# APM32F411 register map
Vendor: Geehy; File version: 2024.11.05
CPU: CM4 r1p0, little endian, 3 interrupt priority bits
Registers are 32-bit, read-write, reset 0x0 unless marked. A register's access mark holds for its fields unless they carry their own. Offsets are from the block's base; [hi:lo] are bit positions; {n}, {i} and the like mark numbered series.

## MPU — Memory Protection Unit
Base 0xE000ED90
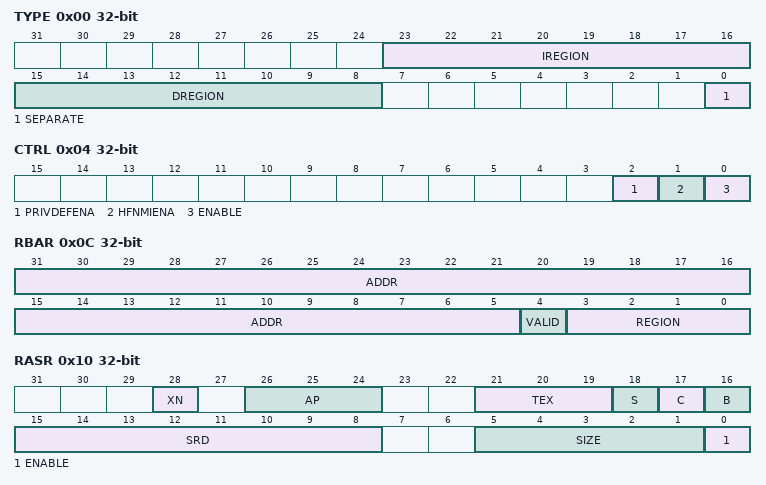
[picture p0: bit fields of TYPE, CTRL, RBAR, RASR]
0x00 TYPE ro — MPU Type Register
  [23:16] IREGION — Number of instruction regions supported
  [15:8] DREGION — Number of data regions supported
  [0] SEPARATE — Indicates support for separate instruction and data regions
0x04 CTRL — MPU Control Register
  [2] PRIVDEFENA — Enables the default memory map for privileged code
  [1] HFNMIENA — Enables MPU during Hard Fault and NMI
  [0] ENABLE — Enables the MPU
0x08 RNR — MPU Region Number Register
  [7:0] REGION — Indicates the region number to configure
0x0C RBAR (reset mask 0x8FFFFFFF) — MPU Region Base Address Register
  [31:5] ADDR — Base address of the region
  [4] VALID — Validates the region number field
  [3:0] REGION — Region number to configure
0x10 RASR — MPU Region Attribute and Size Register
  [28] XN — Instruction access disable
  [26:24] AP — Access permissions
  [21:19] TEX — Type extension field
  [18] S — Sharable attribute
  [17] C — Cacheable attribute
  [16] B — Bufferable attribute
  [15:8] SRD — Subregion disable bits
  [5:1] SIZE — Size of the region
  [0] ENABLE — Enables the region
{0xC+8i} RBAR_A{i} (i=1..3) — MPU Alias {i} Region Base Address Register
{0x10+8i} RASR_A{i} (i=1..3) — MPU Alias {i} Region Attribute and Size Register

## FPU — Floating Point Unit
Base 0xE000EF34
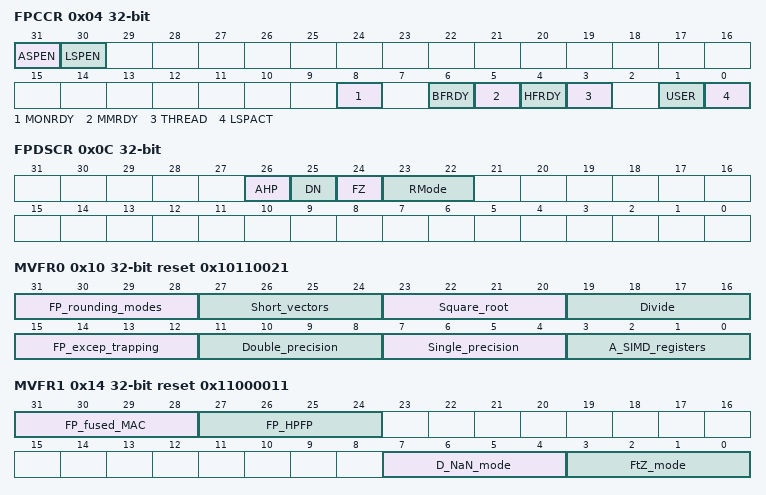
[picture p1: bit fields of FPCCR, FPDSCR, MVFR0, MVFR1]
0x04 FPCCR (reset mask 0xC00001F3) — Floating-Point Context Control Register
  [31] ASPEN — Automatic State Preservation Enable
  [30] LSPEN — Lazy State Preservation Enable
  [8] MONRDY — Indicates if the monitor is ready
  [6] BFRDY — Indicates if bus fault is ready
  [5] MMRDY — Indicates if memory management fault is ready
  [4] HFRDY — Indicates if hard fault is ready
  [3] THREAD — Indicates the processor mode
  [1] USER — Indicates the privilege level
  [0] LSPACT — Lazy State Preservation Active
0x08 FPCAR (reset mask 0x1FFFFFF8) — Floating-Point Context Address Register
  [31:3] ADDRESS — Floating-point context address
0x0C FPDSCR (reset mask 0xC000000) — Floating-Point Default Status Control Register
  [26] AHP — Alternative Half-Precision control
  [25] DN — Default NaN mode
  [24] FZ — Flush-to-Zero mode
  [23:22] RMode — Rounding Mode control
0x10 MVFR0 ro reset 0x10110021 — Media and FP Feature Register 0
  [31:28] FP_rounding_modes — Indicates FP rounding modes
  [27:24] Short_vectors — Indicates support for short vectors
  [23:20] Square_root — Indicates support for square root operations
  [19:16] Divide — Indicates support for divide operations
  [15:12] FP_excep_trapping — Indicates support for FP exception trapping
  [11:8] Double_precision — Indicates support for double precision
  [7:4] Single_precision — Indicates support for single precision
  [3:0] A_SIMD_registers — Indicates support for A SIMD registers
0x14 MVFR1 ro reset 0x11000011 — Media and FP Feature Register 1
  [31:28] FP_fused_MAC — Indicates fused MAC support
  [27:24] FP_HPFP — Indicates support for Half Precision FP
  [7:4] D_NaN_mode — Indicates default NaN mode support
  [3:0] FtZ_mode — Indicates flush-to-zero mode support
0x18 MVFR2 ro — Media and FP Feature Register 2
  [7:4] VFP_Misc — Indicates support for miscellaneous VFP features

## CoreDebug — Core Debug Registers
Base 0xE000EDF0
0x00 DHCSR — Debug Halting Control and Status Register
  [25] S_RESET_ST — Indicates a system reset occurred
  [24] S_RETIRE_ST — Indicates a debug instruction retired
  [19] S_LOCKUP — Indicates processor is in lockup state
  [18] S_SLEEP — Indicates processor is sleeping
  [17] S_HALT — Indicates processor is halted
  [16] S_REGRDY — Register Ready
  [31:16] DBGKEY — Debug key
  [5] C_SNAPSTALL — Snap stall
  [3] C_MASKINTS — Mask interrupts when halted
  [2] C_STEP — Step the core
  [1] C_HALT — Processor halt
  [0] C_DEBUGEN — Debug enable
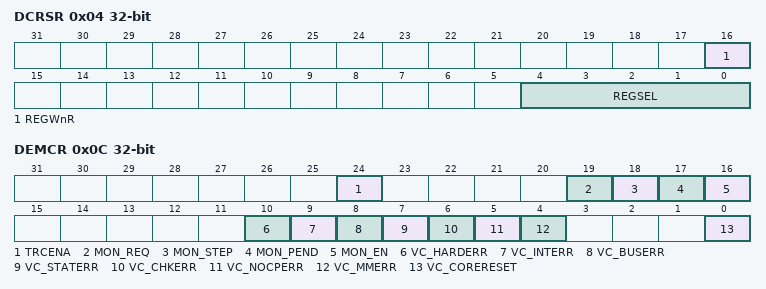
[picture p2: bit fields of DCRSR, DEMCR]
0x04 DCRSR wo — Debug Core Register Selector Register
  [16] REGWnR — Write or read the core register
  [4:0] REGSEL — Specifies the core register
0x08 DCRDR — Debug Core Register Data Register
0x0C DEMCR — Debug Exception and Monitor Control Register
  [24] TRCENA — Enable trace and debug blocks
  [19] MON_REQ — Generate DebugMonitor exception
  [18] MON_STEP — Step DebugMonitor
  [17] MON_PEND — Indicates if DebugMonitor is pending
  [16] MON_EN — Enable DebugMonitor
  [10] VC_HARDERR — Enable vector catch for hard faults
  [9] VC_INTERR — Enable vector catch for interrupt errors
  [8] VC_BUSERR — Enable vector catch for bus faults
  [7] VC_STATERR — Enable vector catch for state errors
  [6] VC_CHKERR — Enable vector catch for check errors
  [5] VC_NOCPERR — Enable vector catch for coprocessor access faults
  [4] VC_MMERR — Enable vector catch for memory management faults
  [0] VC_CORERESET — Enable vector catch for core reset
